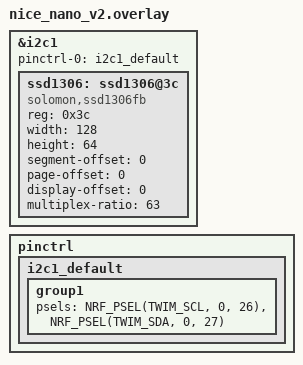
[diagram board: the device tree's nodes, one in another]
&i2c1 {
    status = "okay";
    pinctrl-0 = <&i2c1_default>;  // This is the new line to define pinctrl-0
    pinctrl-names = "default";    // Pin control names

    ssd1306: ssd1306@3c {
        compatible = "solomon,ssd1306fb";
        reg = <0x3c>;
        width = <128>;
        height = <64>;
        segment-offset = <0>;
        page-offset = <0>;
        display-offset = <0>;
        multiplex-ratio = <63>;
    };
};

// Pin configuration for I2C1
pinctrl {
    i2c1_default: i2c1_default {
        group1 {
            psels = <NRF_PSEL(TWIM_SCL, 0, 26)>, /* SCL on P0.26 */
                    <NRF_PSEL(TWIM_SDA, 0, 27)>; /* SDA on P0.27 */
        };
    };
};
